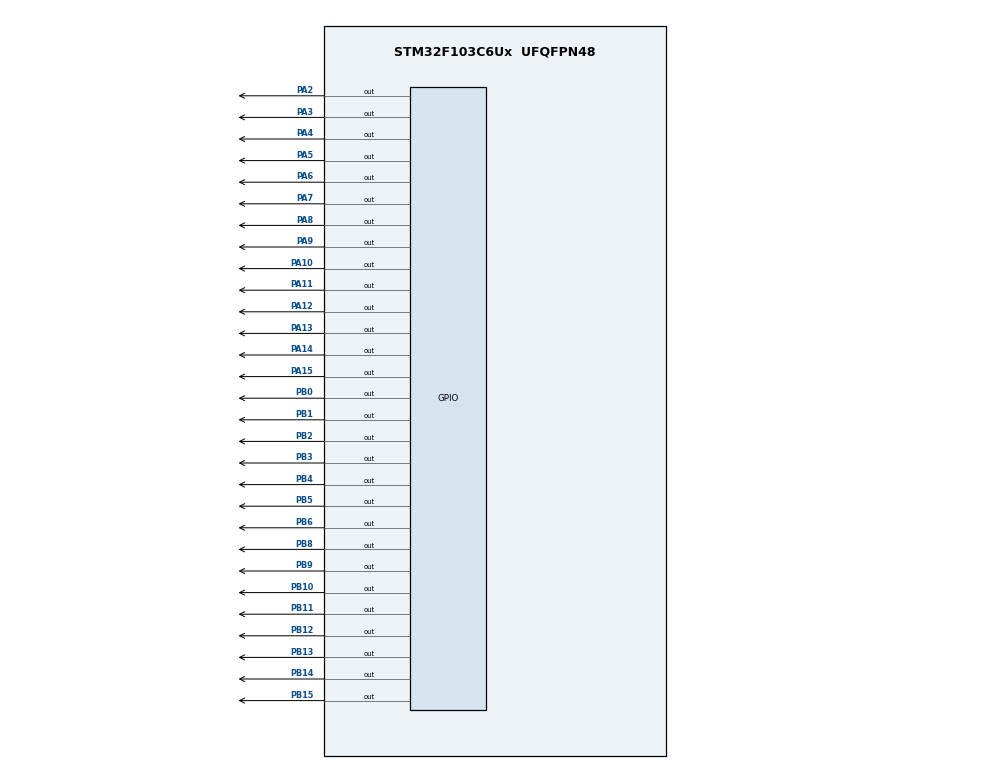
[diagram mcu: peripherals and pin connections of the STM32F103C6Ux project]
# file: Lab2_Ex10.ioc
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Mcu.Family=STM32F1
Mcu.Name=STM32F103C6Ux
Mcu.Package=UFQFPN48
NVIC.PriorityGroup=NVIC_PRIORITYGROUP_4
NVIC.TIM2_IRQn=true\:0\:0\:false\:false\:true\:true\:true
PA10.Signal=GPIO_Output
PA11.Signal=GPIO_Output
PA12.Signal=GPIO_Output
PA13.Signal=GPIO_Output
PA14.Signal=GPIO_Output
PA15.Signal=GPIO_Output
PA2.Signal=GPIO_Output
PA3.Signal=GPIO_Output
PA4.Signal=GPIO_Output
PA5.Signal=GPIO_Output
PA6.Signal=GPIO_Output
PA7.Signal=GPIO_Output
PA8.Signal=GPIO_Output
PA9.Signal=GPIO_Output
PB0.Signal=GPIO_Output
PB1.Signal=GPIO_Output
PB10.Signal=GPIO_Output
PB11.Signal=GPIO_Output
PB12.Signal=GPIO_Output
PB13.Signal=GPIO_Output
PB14.Signal=GPIO_Output
PB15.Signal=GPIO_Output
PB2.Signal=GPIO_Output
PB3.Signal=GPIO_Output
PB4.Signal=GPIO_Output
PB5.Signal=GPIO_Output
PB6.Signal=GPIO_Output
PB8.Signal=GPIO_Output
PB9.Signal=GPIO_Output
ProjectManager.HeapSize=0x200
ProjectManager.StackSize=0x400
ProjectManager.TargetToolchain=STM32CubeIDE
RCC.APB1Freq_Value=8000000
RCC.APB2Freq_Value=8000000
TIM2.Period=9
TIM2.Prescaler=7999
VP_SYS_VS_ND.Mode=No_Debug
VP_TIM2_VS_ClockSourceINT.Mode=Internal
board=custom

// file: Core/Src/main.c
/* USER CODE BEGIN Header */
/**
  ******************************************************************************
  * @file           : main.c
  * @brief          : Main program body (Exercise 10 - LED Matrix Animation)
  ******************************************************************************
  */
/* USER CODE END Header */
#include "main.h"
#include "software_timer.h"

TIM_HandleTypeDef htim2;

/* USER CODE BEGIN PV */
const int MAX_LED = 4;
int index_led = 0;
int led_buffer[4] = {0, 0, 0, 0};
int hour = 15;
int minute = 59;
int second = 50;

const int MAX_LED_MATRIX = 8;
int index_led_matrix = 0;

uint8_t matrix_buffer[8] = {
    0xF8,
    0xFC,
    0x36,
    0x33,
    0x33,
    0x36,
    0xFC,
    0xF8
};
/* USER CODE END PV */

void SystemClock_Config(void);
static void MX_TIM2_Init(void);
static void MX_GPIO_Init(void);

/* USER CODE BEGIN PFP */
void display7SEG(int num);
void update7SEG(int index);
void updateClockBuffer(void);
void updateLEDMatrix(int index);
/* USER CODE END PFP */

/* USER CODE BEGIN 0 */
const uint8_t SEG_CODES[10] = {
    0x40, 0x79, 0x24, 0x30, 0x19,
    0x12, 0x02, 0x78, 0x00, 0x10
};

void display7SEG(int num) {
    if(num < 0 || num > 9) return;
    uint8_t code = SEG_CODES[num];
    HAL_GPIO_WritePin(GPIOB, GPIO_PIN_0, ((code >> 0) & 0x01) ? GPIO_PIN_SET : GPIO_PIN_RESET);
    HAL_GPIO_WritePin(GPIOB, GPIO_PIN_1, ((code >> 1) & 0x01) ? GPIO_PIN_SET : GPIO_PIN_RESET);
    HAL_GPIO_WritePin(GPIOB, GPIO_PIN_2, ((code >> 2) & 0x01) ? GPIO_PIN_SET : GPIO_PIN_RESET);
    HAL_GPIO_WritePin(GPIOB, GPIO_PIN_3, ((code >> 3) & 0x01) ? GPIO_PIN_SET : GPIO_PIN_RESET);
    HAL_GPIO_WritePin(GPIOB, GPIO_PIN_4, ((code >> 4) & 0x01) ? GPIO_PIN_SET : GPIO_PIN_RESET);
    HAL_GPIO_WritePin(GPIOB, GPIO_PIN_5, ((code >> 5) & 0x01) ? GPIO_PIN_SET : GPIO_PIN_RESET);
    HAL_GPIO_WritePin(GPIOB, GPIO_PIN_6, ((code >> 6) & 0x01) ? GPIO_PIN_SET : GPIO_PIN_RESET);
}

void update7SEG(int index) {
    switch (index) {
        case 0:
            display7SEG(led_buffer[0]);
            HAL_GPIO_WritePin(GPIOA, GPIO_PIN_6, GPIO_PIN_RESET);
            break;
        case 1:
            display7SEG(led_buffer[1]);
            HAL_GPIO_WritePin(GPIOA, GPIO_PIN_7, GPIO_PIN_RESET);
            break;
        case 2:
            display7SEG(led_buffer[2]);
            HAL_GPIO_WritePin(GPIOA, GPIO_PIN_8, GPIO_PIN_RESET);
            break;
        case 3:
            display7SEG(led_buffer[3]);
            HAL_GPIO_WritePin(GPIOA, GPIO_PIN_9, GPIO_PIN_RESET);
            break;
        default:
            break;
    }
}

void updateClockBuffer() {
    led_buffer[0] = hour / 10;
    led_buffer[1] = hour % 10;
    led_buffer[2] = minute / 10;
    led_buffer[3] = minute % 10;
}

void updateLEDMatrix(int index) {
    HAL_GPIO_WritePin(GPIOA, GPIO_PIN_2 | GPIO_PIN_3 | GPIO_PIN_10 | GPIO_PIN_11 |
                             GPIO_PIN_12 | GPIO_PIN_13 | GPIO_PIN_14 | GPIO_PIN_15, GPIO_PIN_SET);

    uint8_t inverted_data = ~matrix_buffer[index];
    GPIOB->ODR = (GPIOB->ODR & 0x00FF) | (inverted_data << 8);

    switch (index) {
        case 0: HAL_GPIO_WritePin(GPIOA, GPIO_PIN_2, GPIO_PIN_RESET); break;
        case 1: HAL_GPIO_WritePin(GPIOA, GPIO_PIN_3, GPIO_PIN_RESET); break;
        case 2: HAL_GPIO_WritePin(GPIOA, GPIO_PIN_10, GPIO_PIN_RESET); break;
        case 3: HAL_GPIO_WritePin(GPIOA, GPIO_PIN_11, GPIO_PIN_RESET); break;
        case 4: HAL_GPIO_WritePin(GPIOA, GPIO_PIN_12, GPIO_PIN_RESET); break;
        case 5: HAL_GPIO_WritePin(GPIOA, GPIO_PIN_13, GPIO_PIN_RESET); break;
        case 6: HAL_GPIO_WritePin(GPIOA, GPIO_PIN_14, GPIO_PIN_RESET); break;
        case 7: HAL_GPIO_WritePin(GPIOA, GPIO_PIN_15, GPIO_PIN_RESET); break;
        default: break;
    }
}
/* USER CODE END 0 */

int main(void)
{
  HAL_Init();
  SystemClock_Config();
  MX_TIM2_Init();
  MX_GPIO_Init();

  /* USER CODE BEGIN 2 */
  HAL_TIM_Base_Start_IT(&htim2);
  updateClockBuffer();

  setTimer(0, 1000);
  setTimer(1, 10);
  setTimer(2, 10);
  setTimer(3, 150);
  /* USER CODE END 2 */

  while (1)
  {
      /* USER CODE BEGIN 3 */

      if (timer_flag[0] == 1) {
          setTimer(0, 1000);
          HAL_GPIO_TogglePin(GPIOA, GPIO_PIN_4);

          second++;
          if (second >= 60) {
              second = 0;
              minute++;
              if (minute >= 60) {
                  minute = 0;
                  hour++;
                  if (hour >= 24) hour = 0;
              }
          }
          updateClockBuffer();
      }

      if (timer_flag[1] == 1) {
          setTimer(1, 10);
          HAL_GPIO_WritePin(GPIOA, GPIO_PIN_6 | GPIO_PIN_7 | GPIO_PIN_8 | GPIO_PIN_9, GPIO_PIN_SET);

          update7SEG(index_led);

          index_led++;
          if (index_led >= MAX_LED) index_led = 0;
      }

      if (timer_flag[2] == 1) {
          setTimer(2, 10);

          updateLEDMatrix(index_led_matrix);

          index_led_matrix++;
          if (index_led_matrix >= MAX_LED_MATRIX) index_led_matrix = 0;
      }

      if (timer_flag[3] == 1) {
                setTimer(3, 150);

                uint8_t temp = matrix_buffer[0];
                for (int i = 0; i < 7; i++) {
                    matrix_buffer[i] = matrix_buffer[i + 1];
                }
                matrix_buffer[7] = temp;
            }
      /* USER CODE END 3 */
  }
}

void SystemClock_Config(void)
{
  RCC_OscInitTypeDef RCC_OscInitStruct = {0};
  RCC_ClkInitTypeDef RCC_ClkInitStruct = {0};

  RCC_OscInitStruct.OscillatorType = RCC_OSCILLATORTYPE_HSI;
  RCC_OscInitStruct.HSIState = RCC_HSI_ON;
  RCC_OscInitStruct.HSICalibrationValue = RCC_HSICALIBRATION_DEFAULT;
  RCC_OscInitStruct.PLL.PLLState = RCC_PLL_NONE;
  if (HAL_RCC_OscConfig(&RCC_OscInitStruct) != HAL_OK)
  {
    Error_Handler();
  }
  RCC_ClkInitStruct.ClockType = RCC_CLOCKTYPE_HCLK|RCC_CLOCKTYPE_SYSCLK
                              |RCC_CLOCKTYPE_PCLK1|RCC_CLOCKTYPE_PCLK2;
  RCC_ClkInitStruct.SYSCLKSource = RCC_SYSCLKSOURCE_HSI;
  RCC_ClkInitStruct.AHBCLKDivider = RCC_SYSCLK_DIV1;
  RCC_ClkInitStruct.APB1CLKDivider = RCC_HCLK_DIV1;
  RCC_ClkInitStruct.APB2CLKDivider = RCC_HCLK_DIV1;

  if (HAL_RCC_ClockConfig(&RCC_ClkInitStruct, FLASH_LATENCY_0) != HAL_OK)
  {
    Error_Handler();
  }
}

static void MX_TIM2_Init(void)
{
  TIM_ClockConfigTypeDef sClockSourceConfig = {0};
  TIM_MasterConfigTypeDef sMasterConfig = {0};

  htim2.Instance = TIM2;
  htim2.Init.Prescaler = 7999;
  htim2.Init.CounterMode = TIM_COUNTERMODE_UP;
  htim2.Init.Period = 9;
  htim2.Init.ClockDivision = TIM_CLOCKDIVISION_DIV1;
  htim2.Init.AutoReloadPreload = TIM_AUTORELOAD_PRELOAD_DISABLE;
  if (HAL_TIM_Base_Init(&htim2) != HAL_OK)
  {
    Error_Handler();
  }
  sClockSourceConfig.ClockSource = TIM_CLOCKSOURCE_INTERNAL;
  if (HAL_TIM_ConfigClockSource(&htim2, &sClockSourceConfig) != HAL_OK)
  {
    Error_Handler();
  }
  sMasterConfig.MasterOutputTrigger = TIM_TRGO_RESET;
  sMasterConfig.MasterSlaveMode = TIM_MASTERSLAVEMODE_DISABLE;
  if (HAL_TIMEx_MasterConfigSynchronization(&htim2, &sMasterConfig) != HAL_OK)
  {
    Error_Handler();
  }
}

static void MX_GPIO_Init(void)
{
  GPIO_InitTypeDef GPIO_InitStruct = {0};

  __HAL_RCC_GPIOA_CLK_ENABLE();
  __HAL_RCC_GPIOB_CLK_ENABLE();

  HAL_GPIO_WritePin(GPIOA, GPIO_PIN_2|GPIO_PIN_3|GPIO_PIN_4|GPIO_PIN_10|
                          GPIO_PIN_11|GPIO_PIN_12|GPIO_PIN_13|GPIO_PIN_14|GPIO_PIN_15, GPIO_PIN_RESET);

  HAL_GPIO_WritePin(GPIOA, GPIO_PIN_6|GPIO_PIN_7|GPIO_PIN_8|GPIO_PIN_9, GPIO_PIN_SET);

  HAL_GPIO_WritePin(GPIOB, GPIO_PIN_0|GPIO_PIN_1|GPIO_PIN_2|GPIO_PIN_3|GPIO_PIN_4|
                          GPIO_PIN_5|GPIO_PIN_6|GPIO_PIN_7|GPIO_PIN_8|GPIO_PIN_9|
                          GPIO_PIN_10|GPIO_PIN_11|GPIO_PIN_12|GPIO_PIN_13|GPIO_PIN_14|GPIO_PIN_15, GPIO_PIN_SET);

  GPIO_InitStruct.Pin = GPIO_PIN_2|GPIO_PIN_3|GPIO_PIN_4|GPIO_PIN_6|GPIO_PIN_7|
                        GPIO_PIN_8|GPIO_PIN_9|GPIO_PIN_10|GPIO_PIN_11|GPIO_PIN_12|
                        GPIO_PIN_13|GPIO_PIN_14|GPIO_PIN_15;
  GPIO_InitStruct.Mode = GPIO_MODE_OUTPUT_PP;
  GPIO_InitStruct.Pull = GPIO_NOPULL;
  GPIO_InitStruct.Speed = GPIO_SPEED_FREQ_LOW;
  HAL_GPIO_Init(GPIOA, &GPIO_InitStruct);

  GPIO_InitStruct.Pin = GPIO_PIN_0|GPIO_PIN_1|GPIO_PIN_2|GPIO_PIN_3|GPIO_PIN_4|
                        GPIO_PIN_5|GPIO_PIN_6|GPIO_PIN_7|GPIO_PIN_8|GPIO_PIN_9|
                        GPIO_PIN_10|GPIO_PIN_11|GPIO_PIN_12|GPIO_PIN_13|GPIO_PIN_14|GPIO_PIN_15;
  GPIO_InitStruct.Mode = GPIO_MODE_OUTPUT_PP;
  GPIO_InitStruct.Pull = GPIO_NOPULL;
  GPIO_InitStruct.Speed = GPIO_SPEED_FREQ_LOW;
  HAL_GPIO_Init(GPIOB, &GPIO_InitStruct);
}

/* USER CODE BEGIN 4 */
void HAL_TIM_PeriodElapsedCallback(TIM_HandleTypeDef *htim)
{
    if (htim->Instance == TIM2) {
        timer_run();
    }
}
/* USER CODE END 4 */

void Error_Handler(void)
{
  __disable_irq();
  while (1)
  {
  }
}
